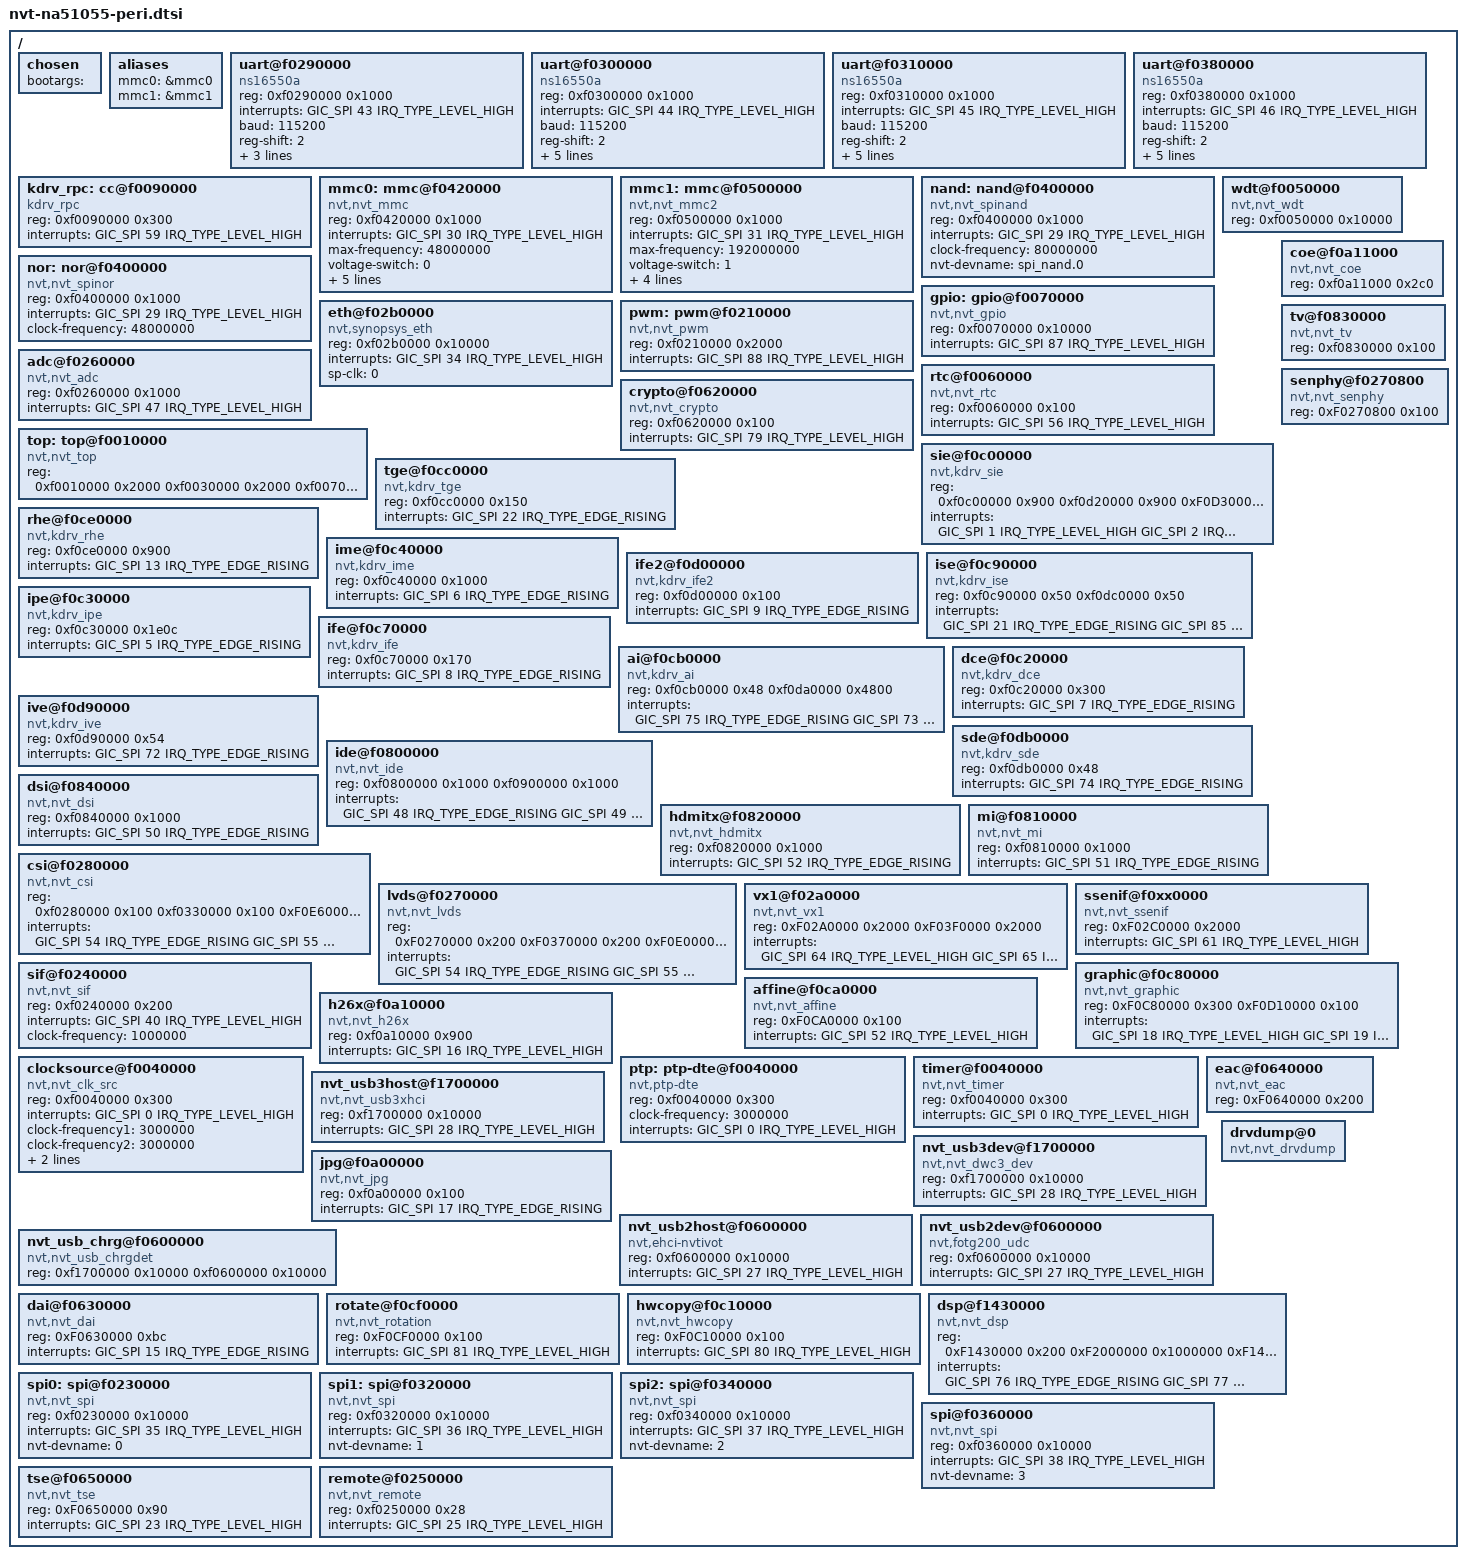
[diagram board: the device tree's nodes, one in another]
/*
 * Novatek Ltd. NA51055 BSP part of dts
 *
 * Cortex-A9
 *
 */


#include <dt-bindings/gpio/nvt-gpio.h>
#include "nvt-na51055-basic.dtsi"

/ {
	chosen {
		bootargs = " ";
	};

	aliases {
		mmc0 = &mmc0;	/* Fixed to mmcblk0 for sdio1 */
		mmc1 = &mmc1;	/* Fixed to mmcblk1 for sdio2 */
	};

	uart@f0290000 {
		compatible = "ns16550a";
		reg = <0xf0290000 0x1000>;
		interrupts = <GIC_SPI 43 IRQ_TYPE_LEVEL_HIGH>;
		baud = <115200>;
		reg-shift = <2>;
		reg-io-width = <4>;
		no-loopback-test = <1>;
		clock-frequency = <24000000>;
	};

	uart@f0300000 {
		compatible = "ns16550a";
		reg = <0xf0300000 0x1000>;
		interrupts = <GIC_SPI 44 IRQ_TYPE_LEVEL_HIGH>;
		baud = <115200>;
		reg-shift = <2>;
		reg-io-width = <4>;
		no-loopback-test = <1>;
		clock-frequency = <48000000>;
		fifo-size = <32>;
		hw_flowctrl = <0>;
	};

	uart@f0310000 {
		compatible = "ns16550a";
		reg = <0xf0310000 0x1000>;
		interrupts = <GIC_SPI 45 IRQ_TYPE_LEVEL_HIGH>;
		baud = <115200>;
		reg-shift = <2>;
		reg-io-width = <4>;
		no-loopback-test = <1>;
		clock-frequency = <48000000>;
		fifo-size = <32>;
		hw_flowctrl = <0>;
	};

	uart@f0380000 {
		compatible = "ns16550a";
		reg = <0xf0380000 0x1000>;
		interrupts = <GIC_SPI 46 IRQ_TYPE_LEVEL_HIGH>;
		baud = <115200>;
		reg-shift = <2>;
		reg-io-width = <4>;
		no-loopback-test = <1>;
		clock-frequency = <48000000>;
		fifo-size = <32>;
		hw_flowctrl = <0>;
	};

	kdrv_rpc: cc@f0090000 {
		compatible = "kdrv_rpc";
		reg = <0xf0090000 0x300>;
		interrupts = <GIC_SPI 59 IRQ_TYPE_LEVEL_HIGH>;
	};

	mmc0: mmc@f0420000 {
		compatible = "nvt,nvt_mmc";
		reg = <0xf0420000 0x1000>;
		interrupts = <GIC_SPI 30 IRQ_TYPE_LEVEL_HIGH>;
		max-frequency = <48000000>;
		voltage-switch = <0>;
		max-voltage = <3300>;
		bus-width = <4>;
		driving = <20 15 15 20 15 15 30 25 25 40 30 30>;
		cd_gpio = <D_GPIO(0) GPIO_FALLING_EDGE GPIO_POLLING>;
		/*card_power_gpio = <P_GPIO(0) GPIO_LOW>;*/
		/*ro_gpio = <D_GPIO(1) GPIO_RISING_EDGE GPIO_POLLING>;*/
		/*power_en = <D_GPIO(2) GPIO_RISING_EDGE>;*/
	};

	mmc1: mmc@f0500000 {
		compatible = "nvt,nvt_mmc2";
		reg = <0xf0500000 0x1000>;
		interrupts = <GIC_SPI 31 IRQ_TYPE_LEVEL_HIGH>;
		max-frequency = <192000000>;
		voltage-switch = <1>;
		max-voltage = <3300>;
		bus-width = <4>;
		driving = <20 15 15 20 15 15 30 25 25 40 30 30>;
		cd_gpio = <0 GPIO_FALLING_EDGE GPIO_INTERRUPT>;
		/*ro_gpio = <D_GPIO(3) GPIO_RISING_EDGE GPIO_POLLING>;*/
		/*power_en = <D_GPIO(4) GPIO_RISING_EDGE>;*/
	};

	nand: nand@f0400000 {
		#address-cells = <2>;
		#size-cells = <2>;
		compatible = "nvt,nvt_spinand";
		reg = <0xf0400000 0x1000>;
		interrupts = <GIC_SPI 29 IRQ_TYPE_LEVEL_HIGH>;
		clock-frequency = <80000000>;
		nvt-devname = "spi_nand.0";
	};

	nor: nor@f0400000 {
		compatible = "nvt,nvt_spinor";
		reg = <0xf0400000 0x1000>;
		interrupts = <GIC_SPI 29 IRQ_TYPE_LEVEL_HIGH>;
		clock-frequency = <48000000>;
	};

        gpio: gpio@f0070000 {
		compatible = "nvt,nvt_gpio";
		reg = <0xf0070000 0x10000>;
		interrupts = <GIC_SPI 87 IRQ_TYPE_LEVEL_HIGH>;
		#gpio-cells = <2>;
        };

	eth@f02b0000 {
		compatible = "nvt,synopsys_eth";
		reg = <0xf02b0000 0x10000>;
		interrupts = <GIC_SPI 34 IRQ_TYPE_LEVEL_HIGH>;
		sp-clk = <0>;
	};

	wdt@f0050000 {
		compatible = "nvt,nvt_wdt";
		reg = <0xf0050000 0x10000>;
	};

	pwm: pwm@f0210000 {
		compatible = "nvt,nvt_pwm";
		reg = <0xf0210000 0x2000>;
		interrupts = <GIC_SPI 88 IRQ_TYPE_LEVEL_HIGH>;
	};

	adc@f0260000 {
		compatible = "nvt,nvt_adc";
		reg = <0xf0260000 0x1000>;
		interrupts = <GIC_SPI 47 IRQ_TYPE_LEVEL_HIGH>;
	};

	rtc@f0060000 {
		compatible = "nvt,nvt_rtc";
		reg = <0xf0060000 0x100>;
		interrupts = <GIC_SPI 56 IRQ_TYPE_LEVEL_HIGH>;
	};

	crypto@f0620000 {
		compatible = "nvt,nvt_crypto";
		reg = <0xf0620000 0x100>;
		interrupts = <GIC_SPI 79 IRQ_TYPE_LEVEL_HIGH>;
	};

	top: top@f0010000 {
		compatible = "nvt,nvt_top";
		reg = <0xf0010000 0x2000
		       0xf0030000 0x2000
		       0xf0070000 0x10000>;
	};

	sie@f0c00000 {
                compatible = "nvt,kdrv_sie";
                reg = <0xf0c00000 0x900
                       0xf0d20000 0x900
                       0xF0D30000 0x900
                       0xF0D40000 0x900
                       0xF0D50000 0x900
                       0xF0D60000 0x900
                       0xF0D70000 0x900
                       0xF0D80000 0x900>;
                interrupts = <GIC_SPI 1 IRQ_TYPE_LEVEL_HIGH
                              GIC_SPI 2 IRQ_TYPE_LEVEL_HIGH
                              GIC_SPI 3 IRQ_TYPE_LEVEL_HIGH
                              GIC_SPI 4 IRQ_TYPE_LEVEL_HIGH
                              GIC_SPI 68 IRQ_TYPE_LEVEL_HIGH
                              GIC_SPI 69 IRQ_TYPE_LEVEL_HIGH
                              GIC_SPI 70 IRQ_TYPE_LEVEL_HIGH
                              GIC_SPI 71 IRQ_TYPE_LEVEL_HIGH>;
		/*sensor_freq = <37125000>;*/
        };


        tge@f0cc0000 {
                compatible = "nvt,kdrv_tge";
                reg = <0xf0cc0000 0x150>;
                interrupts = <GIC_SPI 22 IRQ_TYPE_EDGE_RISING>;
        };

        rhe@f0ce0000 {
                compatible = "nvt,kdrv_rhe";
                reg = <0xf0ce0000 0x900>;
                interrupts = <GIC_SPI 13 IRQ_TYPE_EDGE_RISING>;
        };

        ime@f0c40000 {
                compatible = "nvt,kdrv_ime";
                reg = <0xf0c40000 0x1000>;
                interrupts = <GIC_SPI 6 IRQ_TYPE_EDGE_RISING>;
        };

        ife2@f0d00000 {
                compatible = "nvt,kdrv_ife2";
                reg = <0xf0d00000 0x100>;
                interrupts = <GIC_SPI 9 IRQ_TYPE_EDGE_RISING>;
        };

        ise@f0c90000 {
                compatible = "nvt,kdrv_ise";
                reg = <0xf0c90000 0x50
                       0xf0dc0000 0x50>;
                interrupts = <GIC_SPI 21 IRQ_TYPE_EDGE_RISING
							  GIC_SPI 85 IRQ_TYPE_EDGE_RISING>;
        };

        ipe@f0c30000 {
                compatible = "nvt,kdrv_ipe";
                reg = <0xf0c30000 0x1e0c>;
                interrupts = <GIC_SPI 5 IRQ_TYPE_EDGE_RISING>;
        };

	ife@f0c70000 {
                compatible = "nvt,kdrv_ife";
                reg = <0xf0c70000 0x170>;
                interrupts = <GIC_SPI 8 IRQ_TYPE_EDGE_RISING>;
        };

		ai@f0cb0000 {
                compatible = "nvt,kdrv_ai";
                reg = <0xf0cb0000 0x48
		       0xf0da0000 0x4800>;
                interrupts = <GIC_SPI 75 IRQ_TYPE_EDGE_RISING
			      GIC_SPI 73 IRQ_TYPE_EDGE_RISING>;
        };

        coe@f0a11000 {
                compatible = "nvt,nvt_coe";
                reg = <0xf0a11000 0x2c0>;
        };

        dce@f0c20000 {
                compatible = "nvt,kdrv_dce";
                reg = <0xf0c20000 0x300>;
                interrupts = <GIC_SPI 7 IRQ_TYPE_EDGE_RISING>;
        };

		ive@f0d90000 {
                compatible = "nvt,kdrv_ive";
                reg = <0xf0d90000 0x54>;
                interrupts = <GIC_SPI 72 IRQ_TYPE_EDGE_RISING>;
        };
        sde@f0db0000 {
                compatible = "nvt,kdrv_sde";
                reg = <0xf0db0000 0x48>;
                interrupts = <GIC_SPI 74 IRQ_TYPE_EDGE_RISING>;
        };

        ide@f0800000 {
                compatible = "nvt,nvt_ide";
                reg = <0xf0800000 0x1000
                       0xf0900000 0x1000>;
                interrupts = <GIC_SPI 48 IRQ_TYPE_EDGE_RISING
                              GIC_SPI 49 IRQ_TYPE_EDGE_RISING>;
        };

        dsi@f0840000 {
                compatible = "nvt,nvt_dsi";
                reg = <0xf0840000 0x1000>;
                interrupts = <GIC_SPI 50 IRQ_TYPE_EDGE_RISING>;
        };

        tv@f0830000 {
                compatible = "nvt,nvt_tv";
                reg = <0xf0830000 0x100>;
        };

        hdmitx@f0820000 {
                compatible = "nvt,nvt_hdmitx";
                reg = <0xf0820000 0x1000>;
                interrupts = <GIC_SPI 52 IRQ_TYPE_EDGE_RISING>;
        };

        mi@f0810000 {
                compatible = "nvt,nvt_mi";
                reg = <0xf0810000 0x1000>;
                interrupts = <GIC_SPI 51 IRQ_TYPE_EDGE_RISING>;
        };

	csi@f0280000 {
                compatible = "nvt,nvt_csi";
                reg = <0xf0280000 0x100
                       0xf0330000 0x100
                       0xF0E60000 0x100
                       0xF0E70000 0x100
                       0xF0E80000 0x100
                       0xF0E90000 0x100
                       0xF0EA0000 0x100
                       0xF0EB0000 0x100>;
                interrupts = <GIC_SPI 54 IRQ_TYPE_EDGE_RISING
                              GIC_SPI 55 IRQ_TYPE_EDGE_RISING
                              GIC_SPI 62 IRQ_TYPE_EDGE_RISING
                              GIC_SPI 63 IRQ_TYPE_EDGE_RISING
                              GIC_SPI 64 IRQ_TYPE_EDGE_RISING
                              GIC_SPI 65 IRQ_TYPE_EDGE_RISING
                              GIC_SPI 66 IRQ_TYPE_EDGE_RISING
                              GIC_SPI 67 IRQ_TYPE_EDGE_RISING>;
        };

        lvds@f0270000 {
                compatible = "nvt,nvt_lvds";
                reg = <0xF0270000 0x200
                       0xF0370000 0x200
                       0xF0E00000 0x200
                       0xF0E10000 0x200
                       0xF0E20000 0x200
                       0xF0E30000 0x200
                       0xF0E40000 0x200
                       0xF0E50000 0x200>;
                interrupts = <GIC_SPI 54 IRQ_TYPE_EDGE_RISING
                              GIC_SPI 55 IRQ_TYPE_EDGE_RISING
                              GIC_SPI 62 IRQ_TYPE_EDGE_RISING
                              GIC_SPI 63 IRQ_TYPE_EDGE_RISING
                              GIC_SPI 64 IRQ_TYPE_EDGE_RISING
                              GIC_SPI 65 IRQ_TYPE_EDGE_RISING
                              GIC_SPI 66 IRQ_TYPE_EDGE_RISING
                              GIC_SPI 67 IRQ_TYPE_EDGE_RISING>;
        };

        senphy@f0270800 {
                compatible = "nvt,nvt_senphy";
                reg = <0xF0270800 0x100>;
        };

        vx1@f02a0000 {
                compatible = "nvt,nvt_vx1";
                reg = <0xF02A0000 0x2000
                       0xF03F0000 0x2000>;
                interrupts = <GIC_SPI 64 IRQ_TYPE_LEVEL_HIGH
                              GIC_SPI 65 IRQ_TYPE_LEVEL_HIGH>;
        };

        ssenif@f0xx0000 {
                compatible = "nvt,nvt_ssenif";
                reg = <0xF02C0000 0x2000>;
                interrupts = <GIC_SPI 61 IRQ_TYPE_LEVEL_HIGH>;
        };

        sif@f0240000 {
                compatible = "nvt,nvt_sif";
                reg = <0xf0240000 0x200>;
                interrupts = <GIC_SPI 40 IRQ_TYPE_LEVEL_HIGH>;
                clock-frequency = <1000000>;
        };

        graphic@f0c80000 {
                compatible = "nvt,nvt_graphic";
                reg = <0xF0C80000 0x300
                       0xF0D10000 0x100>;
                interrupts = <GIC_SPI 18 IRQ_TYPE_LEVEL_HIGH
                              GIC_SPI 19 IRQ_TYPE_LEVEL_HIGH>;
        };

        affine@f0ca0000 {
                compatible = "nvt,nvt_affine";
                reg = <0xF0CA0000 0x100>;
                interrupts = <GIC_SPI 52 IRQ_TYPE_LEVEL_HIGH>;
        };

        h26x@f0a10000 {
               compatible = "nvt,nvt_h26x";
               reg = <0xf0a10000 0x900>;
               interrupts = <GIC_SPI 16 IRQ_TYPE_LEVEL_HIGH>;
        };

	clocksource@f0040000 {
		compatible = "nvt,nvt_clk_src";
		reg = <0xf0040000 0x300>;
		interrupts = <GIC_SPI 0 IRQ_TYPE_LEVEL_HIGH>;
		clock-frequency1 = <3000000>;
		clock-frequency2 = <3000000>;
		clksrc = <1>;
		bits = <32>;
		clock-names = "f0040000.timer";
	};

	ptp: ptp-dte@f0040000 {
		compatible = "nvt,ptp-dte";
		reg = <0xf0040000 0x300>;
		clock-frequency = <3000000>;
		interrupts = <GIC_SPI 0 IRQ_TYPE_LEVEL_HIGH>;
	};

        timer@f0040000 {
                compatible = "nvt,nvt_timer";
                reg = <0xf0040000 0x300>;
                interrupts = <GIC_SPI 0 IRQ_TYPE_LEVEL_HIGH>;
        };

		eac@f0640000 {
                compatible = "nvt,nvt_eac";
                reg = <0xF0640000 0x200>;
        };

		nvt_usb3host@f1700000 {
				compatible = "nvt,nvt_usb3xhci";
				reg = <0xf1700000 0x10000>;
				interrupts = <GIC_SPI 28 IRQ_TYPE_LEVEL_HIGH>;
        };

		nvt_usb3dev@f1700000 {
				compatible = "nvt,nvt_dwc3_dev";
				reg = <0xf1700000 0x10000>;
				interrupts = <GIC_SPI 28 IRQ_TYPE_LEVEL_HIGH>;
        };

        jpg@f0a00000 {
                compatible = "nvt,nvt_jpg";
                reg = <0xf0a00000 0x100>;
                interrupts = <GIC_SPI 17 IRQ_TYPE_EDGE_RISING>;
        };

		nvt_usb2host@f0600000 {
				compatible = "nvt,ehci-nvtivot";
				reg = <0xf0600000 0x10000>;
				interrupts = <GIC_SPI 27 IRQ_TYPE_LEVEL_HIGH>;
        };

		nvt_usb2dev@f0600000 {
				compatible = "nvt,fotg200_udc";
				reg = <0xf0600000 0x10000>;
				interrupts = <GIC_SPI 27 IRQ_TYPE_LEVEL_HIGH>;
        };

		nvt_usb_chrg@f0600000 {
				compatible = "nvt,nvt_usb_chrgdet";
                reg = <0xf1700000 0x10000
                       0xf0600000 0x10000>;
		};

        dai@f0630000 {
                compatible = "nvt,nvt_dai";
                reg = <0xF0630000 0xbc>;
                interrupts = <GIC_SPI 15 IRQ_TYPE_EDGE_RISING>;
        };

        rotate@f0cf0000 {
                compatible = "nvt,nvt_rotation";
                reg = <0xF0CF0000 0x100>;
                interrupts = <GIC_SPI 81 IRQ_TYPE_LEVEL_HIGH>;
        };

        hwcopy@f0c10000 {
                compatible = "nvt,nvt_hwcopy";
                reg = <0xF0C10000 0x100>;
                interrupts = <GIC_SPI 80 IRQ_TYPE_LEVEL_HIGH>;
        };

        drvdump@0 {
                compatible = "nvt,nvt_drvdump";
        };

        dsp@f1430000 {
                compatible = "nvt,nvt_dsp";
                reg = <0xF1430000 0x200
                       0xF2000000 0x1000000
                       0xF1440000 0x200
                       0xF3000000 0x1000000>;
                interrupts = <GIC_SPI 76 IRQ_TYPE_EDGE_RISING
                              GIC_SPI 77 IRQ_TYPE_EDGE_RISING>;
        };

	spi0: spi@f0230000 {
		compatible = "nvt,nvt_spi";
		reg = <0xf0230000 0x10000>;
		interrupts = <GIC_SPI 35 IRQ_TYPE_LEVEL_HIGH>;
		nvt-devname = <0>;
        };

	spi1: spi@f0320000 {
		compatible = "nvt,nvt_spi";
		reg = <0xf0320000 0x10000>;
		interrupts = <GIC_SPI 36 IRQ_TYPE_LEVEL_HIGH>;
		nvt-devname = <1>;
        };

	spi2: spi@f0340000 {
		compatible = "nvt,nvt_spi";
		reg = <0xf0340000 0x10000>;
		interrupts = <GIC_SPI 37 IRQ_TYPE_LEVEL_HIGH>;
		nvt-devname = <2>;
        };

	spi@f0360000 {
		compatible = "nvt,nvt_spi";
		reg = <0xf0360000 0x10000>;
		interrupts = <GIC_SPI 38 IRQ_TYPE_LEVEL_HIGH>;
		nvt-devname = <3>;
        };

        tse@f0650000 {
                compatible = "nvt,nvt_tse";
                reg = <0xF0650000 0x90>;
                interrupts = <GIC_SPI 23 IRQ_TYPE_LEVEL_HIGH>;
        };

	remote@f0250000 {
		compatible = "nvt,nvt_remote";
		reg = <0xf0250000 0x28>;
		interrupts = <GIC_SPI 25 IRQ_TYPE_LEVEL_HIGH>;
	};
};
